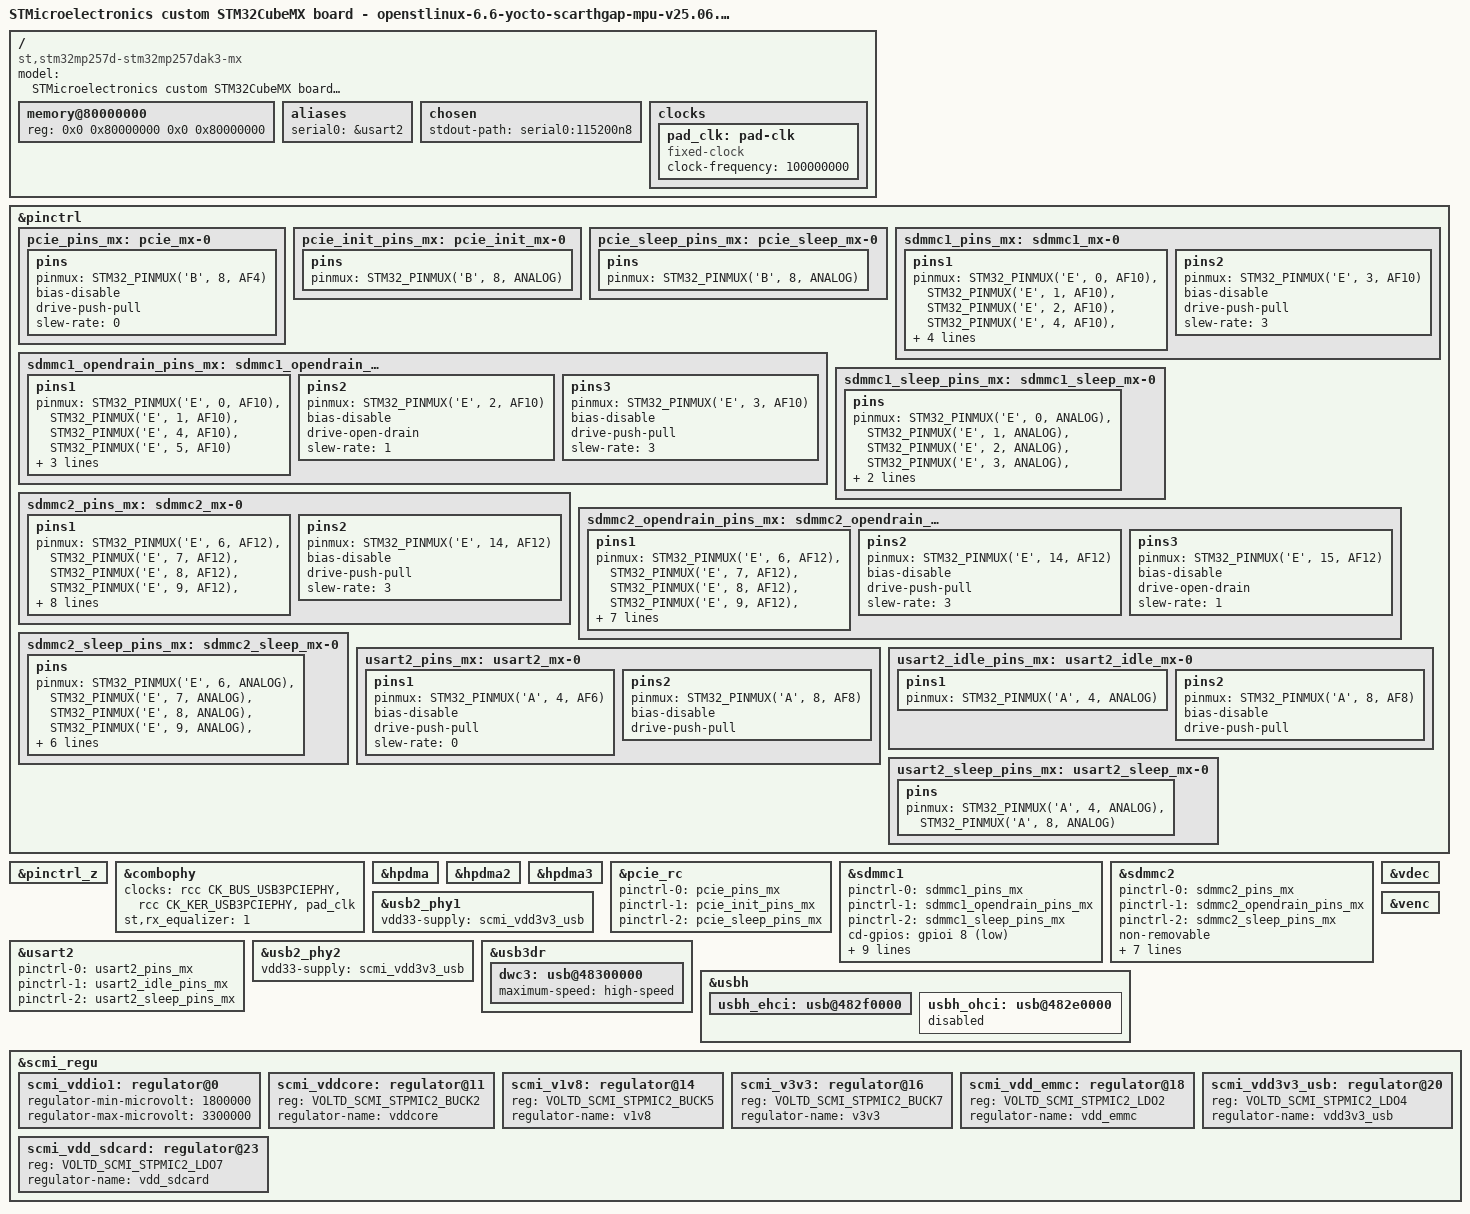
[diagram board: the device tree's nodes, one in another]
// SPDX-License-Identifier: (GPL-2.0-only OR BSD-3-Clause)
/*
 * Copyright (C) 2025, STMicroelectronics - All Rights Reserved
 * Author: STM32CubeMX code generation for STMicroelectronics.
 */

/* For more information on Device Tree configuration, please refer to
 * https://wiki.st.com/stm32mpu/wiki/Category:Device_tree_configuration
 */

/dts-v1/;

#include <dt-bindings/pinctrl/stm32-pinfunc.h>
#include "stm32mp257.dtsi"
#include "stm32mp257d-stm32mp257dak3-mx-resmem.dtsi"
#include "stm32mp25xxak-pinctrl.dtsi"

/* USER CODE BEGIN includes */
#include <dt-bindings/gpio/gpio.h>
/* USER CODE END includes */

/ {
	model = "STMicroelectronics custom STM32CubeMX board - openstlinux-6.6-yocto-scarthgap-mpu-v25.06.11";
	compatible = "st,stm32mp257d-stm32mp257dak3-mx", "st,stm32mp257";

	memory@80000000 {
		device_type = "memory";
		reg = <0x0 0x80000000 0x0 0x80000000>;

		/* USER CODE BEGIN memory */
		/* USER CODE END memory */
	};

	/* USER CODE BEGIN root */
	aliases{
		serial0 = &usart2;
	};
	
	chosen{
		stdout-path = "serial0:115200n8";
		#address-cells = <2>;
		#size-cells = <2>;
		ranges;
	};
	/* USER CODE END root */

	clocks{

		/* USER CODE BEGIN clocks */
		pad_clk: pad-clk {
			#clock-cells = <0>;
			compatible = "fixed-clock";
			clock-frequency = <100000000>;
		};
		/* USER CODE END clocks */
	};

}; /*root*/

&pinctrl {

	pcie_pins_mx: pcie_mx-0 {
		pins {
			pinmux = <STM32_PINMUX('B', 8, AF4)>; /* PCIE_CLKREQN */
			bias-disable;
			drive-push-pull;
			slew-rate = <0>;
		};
	};

	pcie_init_pins_mx: pcie_init_mx-0 {
		pins {
			pinmux = <STM32_PINMUX('B', 8, ANALOG)>; /* PCIE_CLKREQN */
		};
	};

	pcie_sleep_pins_mx: pcie_sleep_mx-0 {
		pins {
			pinmux = <STM32_PINMUX('B', 8, ANALOG)>; /* PCIE_CLKREQN */
		};
	};

	sdmmc1_pins_mx: sdmmc1_mx-0 {
		pins1 {
			pinmux = <STM32_PINMUX('E', 0, AF10)>, /* SDMMC1_D2 */
					 <STM32_PINMUX('E', 1, AF10)>, /* SDMMC1_D3 */
					 <STM32_PINMUX('E', 2, AF10)>, /* SDMMC1_CMD */
					 <STM32_PINMUX('E', 4, AF10)>, /* SDMMC1_D0 */
					 <STM32_PINMUX('E', 5, AF10)>; /* SDMMC1_D1 */
			bias-disable;
			drive-push-pull;
			slew-rate = <1>;
		};
		pins2 {
			pinmux = <STM32_PINMUX('E', 3, AF10)>; /* SDMMC1_CK */
			bias-disable;
			drive-push-pull;
			slew-rate = <3>;
		};
	};

	sdmmc1_opendrain_pins_mx: sdmmc1_opendrain_mx-0 {
		pins1 {
			pinmux = <STM32_PINMUX('E', 0, AF10)>, /* SDMMC1_D2 */
					 <STM32_PINMUX('E', 1, AF10)>, /* SDMMC1_D3 */
					 <STM32_PINMUX('E', 4, AF10)>, /* SDMMC1_D0 */
					 <STM32_PINMUX('E', 5, AF10)>; /* SDMMC1_D1 */
			bias-disable;
			drive-push-pull;
			slew-rate = <1>;
		};
		pins2 {
			pinmux = <STM32_PINMUX('E', 2, AF10)>; /* SDMMC1_CMD */
			bias-disable;
			drive-open-drain;
			slew-rate = <1>;
		};
		pins3 {
			pinmux = <STM32_PINMUX('E', 3, AF10)>; /* SDMMC1_CK */
			bias-disable;
			drive-push-pull;
			slew-rate = <3>;
		};
	};

	sdmmc1_sleep_pins_mx: sdmmc1_sleep_mx-0 {
		pins {
			pinmux = <STM32_PINMUX('E', 0, ANALOG)>, /* SDMMC1_D2 */
					 <STM32_PINMUX('E', 1, ANALOG)>, /* SDMMC1_D3 */
					 <STM32_PINMUX('E', 2, ANALOG)>, /* SDMMC1_CMD */
					 <STM32_PINMUX('E', 3, ANALOG)>, /* SDMMC1_CK */
					 <STM32_PINMUX('E', 4, ANALOG)>, /* SDMMC1_D0 */
					 <STM32_PINMUX('E', 5, ANALOG)>; /* SDMMC1_D1 */
		};
	};

	sdmmc2_pins_mx: sdmmc2_mx-0 {
		pins1 {
			pinmux = <STM32_PINMUX('E', 6, AF12)>, /* SDMMC2_D6 */
					 <STM32_PINMUX('E', 7, AF12)>, /* SDMMC2_D7 */
					 <STM32_PINMUX('E', 8, AF12)>, /* SDMMC2_D2 */
					 <STM32_PINMUX('E', 9, AF12)>, /* SDMMC2_D5 */
					 <STM32_PINMUX('E', 10, AF12)>, /* SDMMC2_D4 */
					 <STM32_PINMUX('E', 11, AF12)>, /* SDMMC2_D1 */
					 <STM32_PINMUX('E', 12, AF12)>, /* SDMMC2_D3 */
					 <STM32_PINMUX('E', 13, AF12)>, /* SDMMC2_D0 */
					 <STM32_PINMUX('E', 15, AF12)>; /* SDMMC2_CMD */
			bias-disable;
			drive-push-pull;
			slew-rate = <1>;
		};
		pins2 {
			pinmux = <STM32_PINMUX('E', 14, AF12)>; /* SDMMC2_CK */
			bias-disable;
			drive-push-pull;
			slew-rate = <3>;
		};
	};

	sdmmc2_opendrain_pins_mx: sdmmc2_opendrain_mx-0 {
		pins1 {
			pinmux = <STM32_PINMUX('E', 6, AF12)>, /* SDMMC2_D6 */
					 <STM32_PINMUX('E', 7, AF12)>, /* SDMMC2_D7 */
					 <STM32_PINMUX('E', 8, AF12)>, /* SDMMC2_D2 */
					 <STM32_PINMUX('E', 9, AF12)>, /* SDMMC2_D5 */
					 <STM32_PINMUX('E', 10, AF12)>, /* SDMMC2_D4 */
					 <STM32_PINMUX('E', 11, AF12)>, /* SDMMC2_D1 */
					 <STM32_PINMUX('E', 12, AF12)>, /* SDMMC2_D3 */
					 <STM32_PINMUX('E', 13, AF12)>; /* SDMMC2_D0 */
			bias-disable;
			drive-push-pull;
			slew-rate = <1>;
		};
		pins2 {
			pinmux = <STM32_PINMUX('E', 14, AF12)>; /* SDMMC2_CK */
			bias-disable;
			drive-push-pull;
			slew-rate = <3>;
		};
		pins3 {
			pinmux = <STM32_PINMUX('E', 15, AF12)>; /* SDMMC2_CMD */
			bias-disable;
			drive-open-drain;
			slew-rate = <1>;
		};
	};

	sdmmc2_sleep_pins_mx: sdmmc2_sleep_mx-0 {
		pins {
			pinmux = <STM32_PINMUX('E', 6, ANALOG)>, /* SDMMC2_D6 */
					 <STM32_PINMUX('E', 7, ANALOG)>, /* SDMMC2_D7 */
					 <STM32_PINMUX('E', 8, ANALOG)>, /* SDMMC2_D2 */
					 <STM32_PINMUX('E', 9, ANALOG)>, /* SDMMC2_D5 */
					 <STM32_PINMUX('E', 10, ANALOG)>, /* SDMMC2_D4 */
					 <STM32_PINMUX('E', 11, ANALOG)>, /* SDMMC2_D1 */
					 <STM32_PINMUX('E', 12, ANALOG)>, /* SDMMC2_D3 */
					 <STM32_PINMUX('E', 13, ANALOG)>, /* SDMMC2_D0 */
					 <STM32_PINMUX('E', 14, ANALOG)>, /* SDMMC2_CK */
					 <STM32_PINMUX('E', 15, ANALOG)>; /* SDMMC2_CMD */
		};
	};

	usart2_pins_mx: usart2_mx-0 {
		pins1 {
			pinmux = <STM32_PINMUX('A', 4, AF6)>; /* USART2_TX */
			bias-disable;
			drive-push-pull;
			slew-rate = <0>;
		};
		pins2 {
			pinmux = <STM32_PINMUX('A', 8, AF8)>; /* USART2_RX */
			bias-disable;
			drive-push-pull;
		};
	};

	usart2_idle_pins_mx: usart2_idle_mx-0 {
		pins1 {
			pinmux = <STM32_PINMUX('A', 4, ANALOG)>; /* USART2_TX */
		};
		pins2 {
			pinmux = <STM32_PINMUX('A', 8, AF8)>; /* USART2_RX */
			bias-disable;
			drive-push-pull;
		};
	};

	usart2_sleep_pins_mx: usart2_sleep_mx-0 {
		pins {
			pinmux = <STM32_PINMUX('A', 4, ANALOG)>, /* USART2_TX */
					 <STM32_PINMUX('A', 8, ANALOG)>; /* USART2_RX */
		};
	};

	/* USER CODE BEGIN pinctrl */
	/* USER CODE END pinctrl */
};

&pinctrl_z {
	/* USER CODE BEGIN pinctrl_z */
	/* USER CODE END pinctrl_z */
};

&combophy {
	status = "okay";

	/* USER CODE BEGIN combophy */
	clocks = <&rcc CK_BUS_USB3PCIEPHY>, <&rcc CK_KER_USB3PCIEPHY>, <&pad_clk>;
	clock-names = "apb-clk", "ker-clk", "pad-clk";
	st,rx_equalizer = <1>;
	/* USER CODE END combophy */
};

&hpdma {
	status = "okay";

	/* USER CODE BEGIN hpdma */
	/* USER CODE END hpdma */
};

&hpdma2 {
	status = "okay";

	/* USER CODE BEGIN hpdma2 */
	/* USER CODE END hpdma2 */
};

&hpdma3 {
	status = "okay";

	/* USER CODE BEGIN hpdma3 */
	/* USER CODE END hpdma3 */
};

&pcie_rc {
	pinctrl-names = "default", "init", "sleep";
	pinctrl-0 = <&pcie_pins_mx>;
	pinctrl-1 = <&pcie_init_pins_mx>;
	pinctrl-2 = <&pcie_sleep_pins_mx>;
	status = "okay";

	/* USER CODE BEGIN pcie_rc */
	/* USER CODE END pcie_rc */
};

&sdmmc1 {
	pinctrl-names = "default", "opendrain", "sleep";
	pinctrl-0 = <&sdmmc1_pins_mx>;
	pinctrl-1 = <&sdmmc1_opendrain_pins_mx>;
	pinctrl-2 = <&sdmmc1_sleep_pins_mx>;
	status = "okay";

	/* USER CODE BEGIN sdmmc1 */
	cd-gpios = <&gpioi 8 (GPIO_ACTIVE_LOW | GPIO_PULL_UP)>;
	disable-wp;
	st,neg-edge;
	bus-width = <4>;
	vmmc-supply = <&scmi_vdd_sdcard>;
	vqmmc-supply = <&scmi_vddio1>;
	sd-uhs-sdr12;
	sd-uhs-sdr25;
	sd-uhs-sdr50;
	sd-uhs-ddr50;
	/* USER CODE END sdmmc1 */
};

&sdmmc2 {
	pinctrl-names = "default", "opendrain", "sleep";
	pinctrl-0 = <&sdmmc2_pins_mx>;
	pinctrl-1 = <&sdmmc2_opendrain_pins_mx>;
	pinctrl-2 = <&sdmmc2_sleep_pins_mx>;
	status = "okay";

	/* USER CODE BEGIN sdmmc2 */
	non-removable;
	no-sd;
	no-sdio;
	st,neg-edge;
	bus-width = <8>;
	vmmc-supply = <&scmi_vdd_emmc>;
	vqmmc-supply = <&scmi_vddio2>;
	mmc-ddr-1_8v;
	/* USER CODE END sdmmc2 */
};

&usart2 {
	pinctrl-names = "default", "idle", "sleep";
	pinctrl-0 = <&usart2_pins_mx>;
	pinctrl-1 = <&usart2_idle_pins_mx>;
	pinctrl-2 = <&usart2_sleep_pins_mx>;
	status = "okay";

	/* USER CODE BEGIN usart2 */
	/delete-property/ dmas;
	/delete-property/ dma-names;
	/* USER CODE END usart2 */
};

&usb2_phy1 {
	status = "okay";

	/* USER CODE BEGIN usb2_phy1 */
	vdd33-supply = <&scmi_vdd3v3_usb>;
	/* USER CODE END usb2_phy1 */
};

&usb2_phy2 {
	status = "okay";

	/* USER CODE BEGIN usb2_phy2 */
	vdd33-supply = <&scmi_vdd3v3_usb>;
	/* USER CODE END usb2_phy2 */
};

&usb3dr {
	status = "okay";

	/* USER CODE BEGIN usb3dr */
	dwc3: usb@48300000 {
		maximum-speed = "high-speed";
	};
	/* USER CODE END usb3dr */
};

&usbh {
	status = "okay";

	/* USER CODE BEGIN usbh */
	usbh_ehci: usb@482f0000 {
		#address-cells = <1>;
		#size-cells = <0>;
	};

	usbh_ohci: usb@482e0000 {
		status = "disabled";
	};
	/* USER CODE END usbh */
};

&vdec {
	status = "okay";

	/* USER CODE BEGIN vdec */
	/* USER CODE END vdec */
};

&venc {
	status = "okay";

	/* USER CODE BEGIN venc */
	/* USER CODE END venc */
};

/* USER CODE BEGIN addons */
&scmi_regu {
	scmi_vddio1: regulator@0 {
		regulator-min-microvolt = <1800000>;
		regulator-max-microvolt = <3300000>;
	};
	scmi_vddcore: regulator@11  {
		reg = <VOLTD_SCMI_STPMIC2_BUCK2>;
		regulator-name = "vddcore";
	};
	scmi_v1v8: regulator@14  {
		reg = <VOLTD_SCMI_STPMIC2_BUCK5>;
		regulator-name = "v1v8";
	};
	scmi_v3v3: regulator@16 {
		reg = <VOLTD_SCMI_STPMIC2_BUCK7>;
		regulator-name = "v3v3";
	};
	scmi_vdd_emmc: regulator@18 {
		reg = <VOLTD_SCMI_STPMIC2_LDO2>;
		regulator-name = "vdd_emmc";
	};
	scmi_vdd3v3_usb: regulator@20 {
		reg = <VOLTD_SCMI_STPMIC2_LDO4>;
		regulator-name = "vdd3v3_usb";
	};
	scmi_vdd_sdcard: regulator@23 {
		reg = <VOLTD_SCMI_STPMIC2_LDO7>;
		regulator-name = "vdd_sdcard";
	};
};
/* USER CODE END addons */

